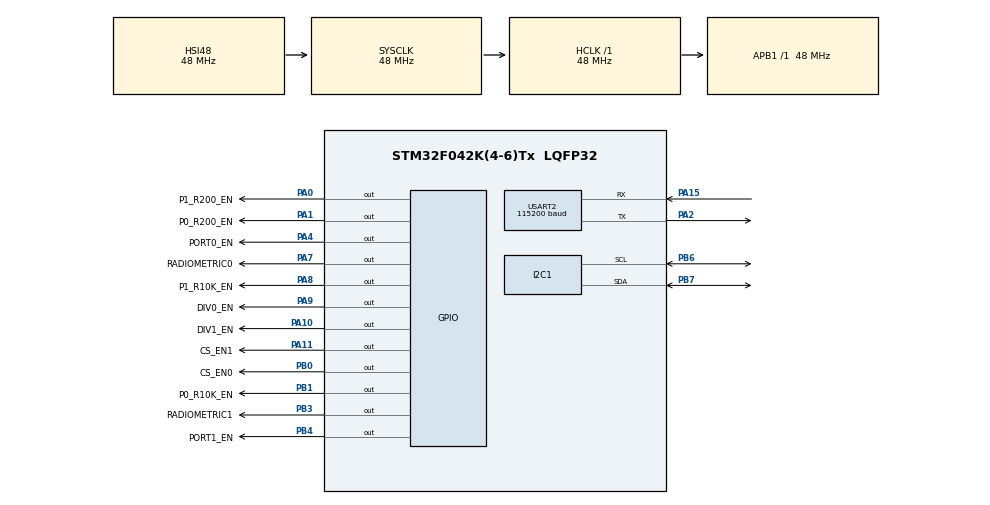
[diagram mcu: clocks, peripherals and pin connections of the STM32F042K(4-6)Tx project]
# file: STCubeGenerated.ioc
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Dma.I2C1_RX.0.Direction=DMA_PERIPH_TO_MEMORY
Dma.I2C1_RX.0.Instance=DMA1_Channel3
Dma.I2C1_RX.0.MemDataAlignment=DMA_MDATAALIGN_BYTE
Dma.I2C1_RX.0.MemInc=DMA_MINC_ENABLE
Dma.I2C1_RX.0.Mode=DMA_NORMAL
Dma.I2C1_RX.0.PeriphDataAlignment=DMA_PDATAALIGN_BYTE
Dma.I2C1_RX.0.PeriphInc=DMA_PINC_DISABLE
Dma.I2C1_RX.0.Priority=DMA_PRIORITY_HIGH
Dma.I2C1_TX.1.Direction=DMA_MEMORY_TO_PERIPH
Dma.I2C1_TX.1.Instance=DMA1_Channel2
Dma.I2C1_TX.1.MemDataAlignment=DMA_MDATAALIGN_BYTE
Dma.I2C1_TX.1.MemInc=DMA_MINC_ENABLE
Dma.I2C1_TX.1.Mode=DMA_NORMAL
Dma.I2C1_TX.1.PeriphDataAlignment=DMA_PDATAALIGN_BYTE
Dma.I2C1_TX.1.PeriphInc=DMA_PINC_DISABLE
Dma.I2C1_TX.1.Priority=DMA_PRIORITY_HIGH
Dma.Request0=I2C1_RX
Dma.Request1=I2C1_TX
Dma.Request2=USART2_TX
Dma.Request3=USART2_RX
Dma.USART2_RX.3.Direction=DMA_PERIPH_TO_MEMORY
Dma.USART2_RX.3.Instance=DMA1_Channel5
Dma.USART2_RX.3.MemDataAlignment=DMA_MDATAALIGN_BYTE
Dma.USART2_RX.3.MemInc=DMA_MINC_ENABLE
Dma.USART2_RX.3.Mode=DMA_NORMAL
Dma.USART2_RX.3.PeriphDataAlignment=DMA_PDATAALIGN_BYTE
Dma.USART2_RX.3.PeriphInc=DMA_PINC_DISABLE
Dma.USART2_RX.3.Priority=DMA_PRIORITY_LOW
Dma.USART2_TX.2.Direction=DMA_MEMORY_TO_PERIPH
Dma.USART2_TX.2.Instance=DMA1_Channel4
Dma.USART2_TX.2.MemDataAlignment=DMA_MDATAALIGN_BYTE
Dma.USART2_TX.2.MemInc=DMA_MINC_ENABLE
Dma.USART2_TX.2.Mode=DMA_NORMAL
Dma.USART2_TX.2.PeriphDataAlignment=DMA_PDATAALIGN_BYTE
Dma.USART2_TX.2.PeriphInc=DMA_PINC_DISABLE
Dma.USART2_TX.2.Priority=DMA_PRIORITY_LOW
I2C1.Timing=0x20303E5D
Mcu.Family=STM32F0
Mcu.Name=STM32F042K(4-6)Tx
Mcu.Package=LQFP32
NVIC.DMA1_Channel2_3_IRQn=true\:0\:0\:false\:false\:true\:false\:true\:true
NVIC.DMA1_Channel4_5_IRQn=true\:0\:0\:false\:false\:true\:false\:true\:true
NVIC.I2C1_IRQn=true\:0\:0\:false\:false\:true\:true\:true\:true
NVIC.USART2_IRQn=true\:0\:0\:false\:false\:true\:true\:true\:true
PA0.GPIO_Label=P1_R200_EN
PA0.GPIO_ModeDefaultOutputPP=GPIO_MODE_OUTPUT_PP
PA0.GPIO_Speed=GPIO_SPEED_FREQ_LOW
PA0.Signal=GPIO_Output
PA1.GPIO_Label=P0_R200_EN
PA1.Signal=GPIO_Output
PA10.GPIO_FMA10=__NULL
PA10.GPIO_Label=DIV1_EN
PA10.GPIO_Speed=GPIO_SPEED_FREQ_HIGH
PA10.Signal=GPIO_Output
PA11.GPIO_Label=CS_EN1
PA11.Signal=GPIO_Output
PA15.Mode=Asynchronous
PA15.Signal=USART2_RX
PA2.Mode=Asynchronous
PA2.Signal=USART2_TX
PA4.GPIO_Label=PORT0_EN
PA4.Signal=GPIO_Output
PA7.GPIO_Label=RADIOMETRIC0
PA7.Signal=GPIO_Output
PA8.GPIO_Label=P1_R10K_EN
PA8.Signal=GPIO_Output
PA9.GPIO_FMA9=__NULL
PA9.GPIO_Label=DIV0_EN
PA9.GPIO_Speed=GPIO_SPEED_FREQ_HIGH
PA9.Signal=GPIO_Output
PB0.GPIO_Label=CS_EN0
PB0.Signal=GPIO_Output
PB1.GPIO_Label=P0_R10K_EN
PB1.Signal=GPIO_Output
PB3.GPIO_Label=RADIOMETRIC1
PB3.Signal=GPIO_Output
PB4.GPIO_Label=PORT1_EN
PB4.Signal=GPIO_Output
PB6.GPIO_FM6=__NULL
PB6.GPIO_Mode=GPIO_MODE_AF_OD
PB6.GPIO_Pu=GPIO_NOPULL
PB6.GPIO_Speed=GPIO_SPEED_FREQ_HIGH
PB6.Mode=I2C
PB6.Signal=I2C1_SCL
PB7.Mode=I2C
PB7.Signal=I2C1_SDA
PF0-OSC_IN.Mode=HSE-External-Oscillator
PF0-OSC_IN.Signal=RCC_OSC_IN
PF1-OSC_OUT.Mode=HSE-External-Oscillator
PF1-OSC_OUT.Signal=RCC_OSC_OUT
ProjectManager.HeapSize=0x200
ProjectManager.StackSize=0x400
ProjectManager.TargetToolchain=MDK-ARM V5
RCC.AHBFreq_Value=48000000
RCC.APB1Freq_Value=48000000
RCC.APB1TimFreq_Value=48000000
RCC.HCLKFreq_Value=48000000
RCC.I2c1ClockSelection=RCC_I2C1CLKSOURCE_SYSCLK
RCC.PLLSourceVirtual=RCC_PLLSOURCE_HSE
RCC.SYSCLKFreq_VALUE=48000000
RCC.SYSCLKSource=RCC_SYSCLKSOURCE_HSI48
USART2.BaudRate=115200
USART2.VirtualMode-Asynchronous=VM_ASYNC
board=custom

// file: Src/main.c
/* USER CODE BEGIN Header */
/**
  ******************************************************************************
  * @file           : main.c
  * @brief          : Main program body
  ******************************************************************************
  * @attention
  *
  * Copyright (c) 2022 STMicroelectronics.
  * All rights reserved.
  *
  * This software is licensed under terms that can be found in the LICENSE file
  * in the root directory of this software component.
  * If no LICENSE file comes with this software, it is provided AS-IS.
  *
  ******************************************************************************
  */
/* USER CODE END Header */
#include "main.h"

/* USER CODE BEGIN Includes */
#include "systemController.h"
/* USER CODE END Includes */

I2C_HandleTypeDef hi2c1;
DMA_HandleTypeDef hdma_i2c1_rx;
DMA_HandleTypeDef hdma_i2c1_tx;

UART_HandleTypeDef huart2;
DMA_HandleTypeDef hdma_usart2_tx;
DMA_HandleTypeDef hdma_usart2_rx;

void SystemClock_Config(void);
static void MX_GPIO_Init(void);
static void MX_DMA_Init(void);
static void MX_I2C1_Init(void);
static void MX_USART2_UART_Init(void);

int main(void)
{

  /* MCU Configuration--------------------------------------------------------*/

  /* Reset of all peripherals, Initializes the Flash interface and the Systick. */
  HAL_Init();

  /* Configure the system clock */
  SystemClock_Config();

  /* Initialize all configured peripherals */
  MX_GPIO_Init();
  MX_DMA_Init();
  MX_I2C1_Init();
  MX_USART2_UART_Init();
  /* USER CODE BEGIN 2 */

  systemController_init(&hi2c1, &huart2);

  /* USER CODE END 2 */

  /* Infinite loop */
  while (1)
  {

    /* USER CODE BEGIN 3 */
    systemController_tick();
  }
  /* USER CODE END 3 */
}

void SystemClock_Config(void)
{
  RCC_OscInitTypeDef RCC_OscInitStruct = {0};
  RCC_ClkInitTypeDef RCC_ClkInitStruct = {0};
  RCC_PeriphCLKInitTypeDef PeriphClkInit = {0};

  /** Initializes the RCC Oscillators according to the specified parameters
  * in the RCC_OscInitTypeDef structure.
  */
  RCC_OscInitStruct.OscillatorType = RCC_OSCILLATORTYPE_HSI48;
  RCC_OscInitStruct.HSI48State = RCC_HSI48_ON;
  RCC_OscInitStruct.PLL.PLLState = RCC_PLL_NONE;
  if (HAL_RCC_OscConfig(&RCC_OscInitStruct) != HAL_OK)
  {
    Error_Handler();
  }

  /** Initializes the CPU, AHB and APB buses clocks
  */
  RCC_ClkInitStruct.ClockType = RCC_CLOCKTYPE_HCLK|RCC_CLOCKTYPE_SYSCLK
                              |RCC_CLOCKTYPE_PCLK1;
  RCC_ClkInitStruct.SYSCLKSource = RCC_SYSCLKSOURCE_HSI48;
  RCC_ClkInitStruct.AHBCLKDivider = RCC_SYSCLK_DIV1;
  RCC_ClkInitStruct.APB1CLKDivider = RCC_HCLK_DIV1;

  if (HAL_RCC_ClockConfig(&RCC_ClkInitStruct, FLASH_LATENCY_1) != HAL_OK)
  {
    Error_Handler();
  }
  PeriphClkInit.PeriphClockSelection = RCC_PERIPHCLK_I2C1;
  PeriphClkInit.I2c1ClockSelection = RCC_I2C1CLKSOURCE_SYSCLK;
  if (HAL_RCCEx_PeriphCLKConfig(&PeriphClkInit) != HAL_OK)
  {
    Error_Handler();
  }
}

static void MX_I2C1_Init(void)
{

  hi2c1.Instance = I2C1;
  hi2c1.Init.Timing = 0x20303E5D;
  hi2c1.Init.OwnAddress1 = 0;
  hi2c1.Init.AddressingMode = I2C_ADDRESSINGMODE_7BIT;
  hi2c1.Init.DualAddressMode = I2C_DUALADDRESS_DISABLE;
  hi2c1.Init.OwnAddress2 = 0;
  hi2c1.Init.OwnAddress2Masks = I2C_OA2_NOMASK;
  hi2c1.Init.GeneralCallMode = I2C_GENERALCALL_DISABLE;
  hi2c1.Init.NoStretchMode = I2C_NOSTRETCH_DISABLE;
  if (HAL_I2C_Init(&hi2c1) != HAL_OK)
  {
    Error_Handler();
  }

  /** Configure Analogue filter
  */
  if (HAL_I2CEx_ConfigAnalogFilter(&hi2c1, I2C_ANALOGFILTER_ENABLE) != HAL_OK)
  {
    Error_Handler();
  }

  /** Configure Digital filter
  */
  if (HAL_I2CEx_ConfigDigitalFilter(&hi2c1, 0) != HAL_OK)
  {
    Error_Handler();
  }

}

static void MX_USART2_UART_Init(void)
{

  huart2.Instance = USART2;
  huart2.Init.BaudRate = 115200;
  huart2.Init.WordLength = UART_WORDLENGTH_8B;
  huart2.Init.StopBits = UART_STOPBITS_1;
  huart2.Init.Parity = UART_PARITY_NONE;
  huart2.Init.Mode = UART_MODE_TX_RX;
  huart2.Init.HwFlowCtl = UART_HWCONTROL_NONE;
  huart2.Init.OverSampling = UART_OVERSAMPLING_16;
  huart2.Init.OneBitSampling = UART_ONE_BIT_SAMPLE_DISABLE;
  huart2.AdvancedInit.AdvFeatureInit = UART_ADVFEATURE_NO_INIT;
  if (HAL_UART_Init(&huart2) != HAL_OK)
  {
    Error_Handler();
  }

}

static void MX_DMA_Init(void)
{

  /* DMA controller clock enable */
  __HAL_RCC_DMA1_CLK_ENABLE();

  /* DMA interrupt init */
  /* DMA1_Channel2_3_IRQn interrupt configuration */
  HAL_NVIC_SetPriority(DMA1_Channel2_3_IRQn, 0, 0);
  HAL_NVIC_EnableIRQ(DMA1_Channel2_3_IRQn);
  /* DMA1_Channel4_5_IRQn interrupt configuration */
  HAL_NVIC_SetPriority(DMA1_Channel4_5_IRQn, 0, 0);
  HAL_NVIC_EnableIRQ(DMA1_Channel4_5_IRQn);

}

static void MX_GPIO_Init(void)
{
  GPIO_InitTypeDef GPIO_InitStruct = {0};

  /* GPIO Ports Clock Enable */
  __HAL_RCC_GPIOF_CLK_ENABLE();
  __HAL_RCC_GPIOA_CLK_ENABLE();
  __HAL_RCC_GPIOB_CLK_ENABLE();

  /*Configure GPIO pin Output Level */
  HAL_GPIO_WritePin(GPIOA, P1_R200_EN_Pin|P0_R200_EN_Pin|PORT0_EN_Pin|RADIOMETRIC0_Pin
                          |P1_R10K_EN_Pin|DIV0_EN_Pin|DIV1_EN_Pin|CS_EN1_Pin, GPIO_PIN_RESET);

  /*Configure GPIO pin Output Level */
  HAL_GPIO_WritePin(GPIOB, CS_EN0_Pin|P0_R10K_EN_Pin|RADIOMETRIC1_Pin|PORT1_EN_Pin, GPIO_PIN_RESET);

  /*Configure GPIO pins : P1_R200_EN_Pin P0_R200_EN_Pin PORT0_EN_Pin RADIOMETRIC0_Pin
                           P1_R10K_EN_Pin CS_EN1_Pin */
  GPIO_InitStruct.Pin = P1_R200_EN_Pin|P0_R200_EN_Pin|PORT0_EN_Pin|RADIOMETRIC0_Pin
                          |P1_R10K_EN_Pin|CS_EN1_Pin;
  GPIO_InitStruct.Mode = GPIO_MODE_OUTPUT_PP;
  GPIO_InitStruct.Pull = GPIO_NOPULL;
  GPIO_InitStruct.Speed = GPIO_SPEED_FREQ_LOW;
  HAL_GPIO_Init(GPIOA, &GPIO_InitStruct);

  /*Configure GPIO pins : CS_EN0_Pin P0_R10K_EN_Pin RADIOMETRIC1_Pin PORT1_EN_Pin */
  GPIO_InitStruct.Pin = CS_EN0_Pin|P0_R10K_EN_Pin|RADIOMETRIC1_Pin|PORT1_EN_Pin;
  GPIO_InitStruct.Mode = GPIO_MODE_OUTPUT_PP;
  GPIO_InitStruct.Pull = GPIO_NOPULL;
  GPIO_InitStruct.Speed = GPIO_SPEED_FREQ_LOW;
  HAL_GPIO_Init(GPIOB, &GPIO_InitStruct);

  /*Configure GPIO pins : DIV0_EN_Pin DIV1_EN_Pin */
  GPIO_InitStruct.Pin = DIV0_EN_Pin|DIV1_EN_Pin;
  GPIO_InitStruct.Mode = GPIO_MODE_OUTPUT_PP;
  GPIO_InitStruct.Pull = GPIO_NOPULL;
  GPIO_InitStruct.Speed = GPIO_SPEED_FREQ_HIGH;
  HAL_GPIO_Init(GPIOA, &GPIO_InitStruct);

}

void Error_Handler(void)
{
  __disable_irq();
  while (1)
  {
  }
}
